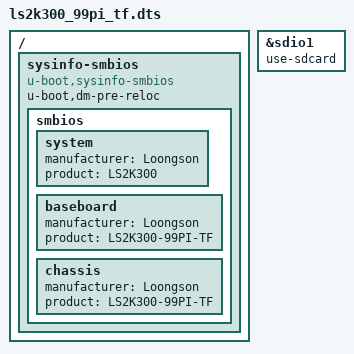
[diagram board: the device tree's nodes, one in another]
#include "ls2k300_99pi.dtsi"
#include "ls2k300_ddr_samsung_512m.dtsi"
#include <dt-bindings/gpio/gpio.h>

/ {
	sysinfo-smbios {
		compatible = "u-boot,sysinfo-smbios";
		u-boot,dm-pre-reloc;

		smbios {
			system {
				manufacturer = "Loongson";
				product = "LS2K300";
			};

			baseboard {
				manufacturer = "Loongson";
				product = "LS2K300-99PI-TF";
			};

			chassis {
				manufacturer = "Loongson";
				product = "LS2K300-99PI-TF";
			};
		};
	};
};

&sdio1 {
	status = "okay";
	use-sdcard;
};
